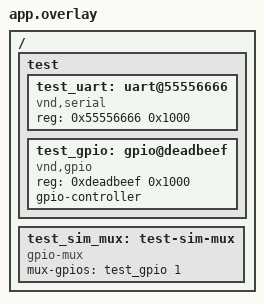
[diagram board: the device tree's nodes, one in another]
/*
 * Copyright (c) 2020, Linaro Ltd.
 *
 * SPDX-License-Identifier: Apache-2.0
 *
 * Application overlay for testing driver builds
 *
 * Names in this file should be chosen in a way that won't conflict
 * with real-world devicetree nodes, to allow these tests to run on
 * (and be extended to test) real hardware.
 */

/ {
	test {
		#address-cells = <1>;
		#size-cells = <1>;

		test_uart: uart@55556666 {
			compatible = "vnd,serial";
			reg = <0x55556666 0x1000>;
			status = "okay";

#include "uart.dtsi"
		};

		test_gpio: gpio@deadbeef {
			compatible = "vnd,gpio";
			reg = <0xdeadbeef 0x1000>;
			gpio-controller;
			#gpio-cells = <0x2>;
			status = "okay";
		};
	};

	test_sim_mux: test-sim-mux {
		compatible = "gpio-mux";
		#mux-control-cells = <0>;
		#mux-state-cells = <1>;
		mux-gpios = <&test_gpio 1 0>;
	};
};
